# R7FA2A1AB register map
Vendor: Renesas; Series: RA2; File version: 1.1
CPU: CM23 r1p0, little endian, MPU, no FPU, VTOR, 2 interrupt priority bits
Registers are 8-bit, read-write, reset 0x0 unless marked. A register's access mark holds for its fields unless they carry their own. Offsets are from the block's base; [hi:lo] are bit positions; {n}, {i} and the like mark numbered series; 'fields as' and 'values as' point back to an identical list.

## DAC8 — 8-bit D/A converter
Base 0x4009E000
{0x0+i} DACS{i} (i=0..1) — D/A Conversion Value Setting Register {i}
  [7:0] DACS — DACS D/A conversion store data
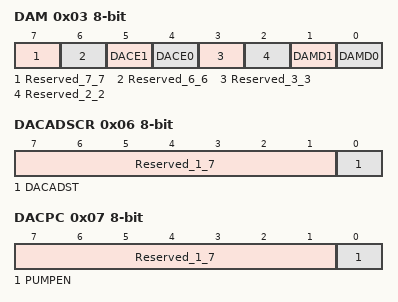
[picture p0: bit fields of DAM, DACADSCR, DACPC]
0x03 DAM — D/A Converter Mode Register
  [7] Reserved_7_7 — This bit is read as 0. The write value should be 0.
  [6] Reserved_6_6 — This bit is read as 0. The write value should be 0.
  [5] DACE1 — D/A operation enable 1
  [4] DACE0 — D/A operation enable 0
  [3] Reserved_3_3 — This bit is read as 0. The write value should be 0.
  [2] Reserved_2_2 — This bit is read as 0. The write value should be 0.
  [1] DAMD1 — D/A operation mode select 1
  [0] DAMD0 — D/A operation mode select 0
0x06 DACADSCR — D/A A/D Synchronous Start Control Register
  [7:1] Reserved_1_7 — These bits are read as 0000000. The write value should be 0000000.
  [0] DACADST — D/A A/D Synchronous Conversion
0x07 DACPC — D/A SW Charge Pump Control Register
  [7:1] Reserved_1_7 — These bits are read as 0000000. The write value should be 0000000.
  [0] PUMPEN — Charge pump enable

## ELC — Event Link Controller
Base 0x40041000
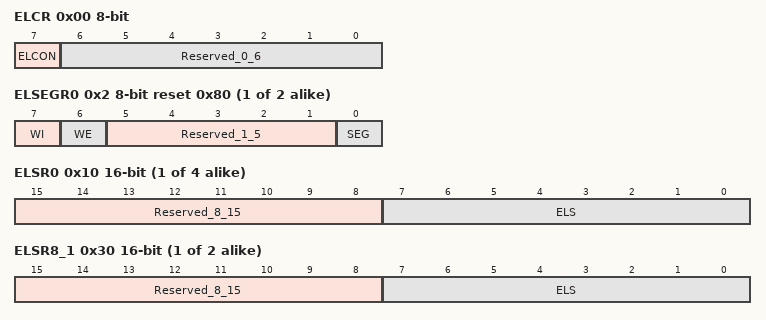
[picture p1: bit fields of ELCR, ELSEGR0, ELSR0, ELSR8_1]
0x00 ELCR — Event Link Controller Register
  [7] ELCON — All Event Link Enable
  [6:0] Reserved_0_6 — These bits are read as 0000000. The write value should be 0000000.
{0x2+2i} ELSEGR{i} (i=0..1) reset 0x80 — Event Link Software Event Generation Register {i}
  [7] WI wo — ELSEGR Register Write Disable
  [6] WE — SEG Bit Write Enable
  [5:1] Reserved_1_5 — These bits are read as 00000. The write value should be 00000.
  [0] SEG wo — Software Event Generation
{0x10+4i} ELSR{i} (i=0..3) 16-bit — Event Link Setting Register {i}
  [15:8] Reserved_8_15 — These bits are read as 00000000. The write value should be 00000000.
  [7:0] ELS — Event Link Select
{0x10+4i} ELSR{i}_1 (i=8..9) 16-bit — Event Link Setting Register {i}
  fields as ELSR0
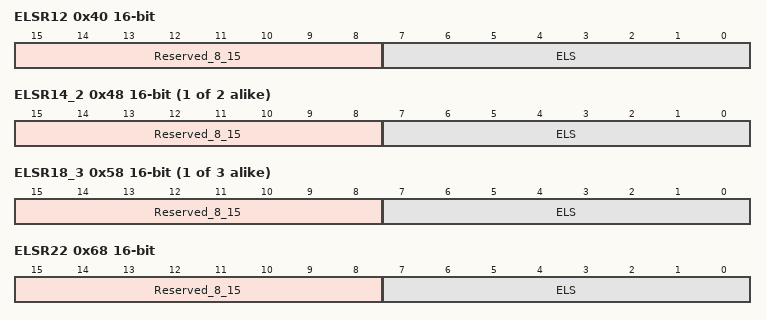
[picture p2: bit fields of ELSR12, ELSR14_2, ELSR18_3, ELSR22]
0x40 ELSR12 16-bit — Event Link Setting Register 12
  fields as ELSR0
{0x10+4i} ELSR{i}_2 (i=14..15) 16-bit — Event Link Setting Register {i}
  fields as ELSR0
{0x10+4i} ELSR{i}_3 (i=18..20) 16-bit — Event Link Setting Register {i}
  fields as ELSR0
0x68 ELSR22 16-bit — Event Link Setting Register 22
  fields as ELSR0

## IWDT — Independent Watchdog Timer
Base 0x40044400
0x00 IWDTRR reset 0xFF — IWDT Refresh Register
  [7:0] IWDTRR — The counter is refreshed by writing 0x00 and then writing 0xFF to this register.
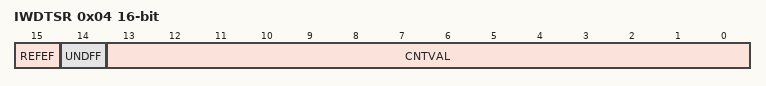
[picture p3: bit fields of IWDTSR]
0x04 IWDTSR 16-bit — IWDT Status Register
  [15] REFEF write-0-clears read-modifies — Refresh Error Flag
  [14] UNDFF write-0-clears read-modifies — Underflow Flag
  [13:0] CNTVAL ro — Counter ValueValue counted by the counter

## KINT — Key Interrupt Function
Base 0x40080000
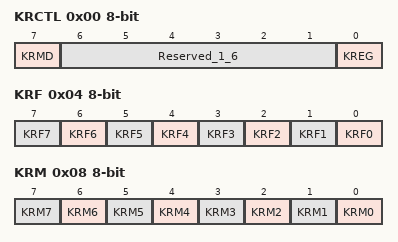
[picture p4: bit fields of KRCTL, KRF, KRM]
0x00 KRCTL — KEY Return Control Register
  [7] KRMD — Usage of Key Interrupt Flags(KR0 to KR7)
  [6:1] Reserved_1_6 — These bits are read as 000000. The write value should be 000000.
  [0] KREG — Detection Edge Selection (KRF0 to KRF7)
0x04 KRF write-0-clears read-modifies — KEY Return Flag Register
  [n] KRF{n} write-0-clears read-modifies (n=0..7) — Key interrupt flag {n}
0x08 KRM — KEY Return Mode Register
  [n] KRM{n} (n=0..7) — Key interrupt mode control {n}

## WDT — Watchdog Timer
Base 0x40044200
0x00 WDTRR reset 0xFF — WDT Refresh Register
  [7:0] WDTRR — WDTRR is an 8-bit register that refreshes the down,counter of the WDT.
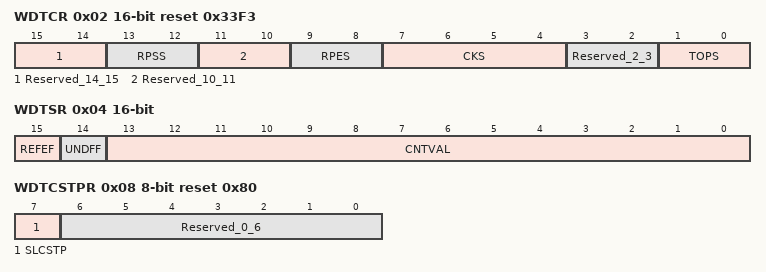
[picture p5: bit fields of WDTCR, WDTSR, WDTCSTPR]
0x02 WDTCR 16-bit reset 0x33F3 — WDT Control Register
  [15:14] Reserved_14_15 — These bits are read as 00. The write value should be 00.
  [13:12] RPSS — Window Start Position Selection
  [11:10] Reserved_10_11 — These bits are read as 00. The write value should be 00.
  [9:8] RPES — Window End Position Selection
  [7:4] CKS — Clock Division Ratio Selection
  [3:2] Reserved_2_3 — These bits are read as 00. The write value should be 00.
  [1:0] TOPS — Timeout Period Selection
0x04 WDTSR 16-bit — WDT Status Register
  [15] REFEF write-0-clears read-modifies — Refresh Error Flag
  [14] UNDFF write-0-clears read-modifies — Underflow Flag
  [13:0] CNTVAL ro — Down,Counter ValueValue counted by the down,counter
0x06 WDTRCR reset 0x80 — WDT Reset Control Register
  [7] RSTIRQS — Reset Interrupt Request Selection
0x08 WDTCSTPR reset 0x80 — WDT Count Stop Control Register
  [7] SLCSTP — Sleep,Mode Count Stop Control
  [6:0] Reserved_0_6 — These bits are read as 0000000. The write value should be 0000000.
